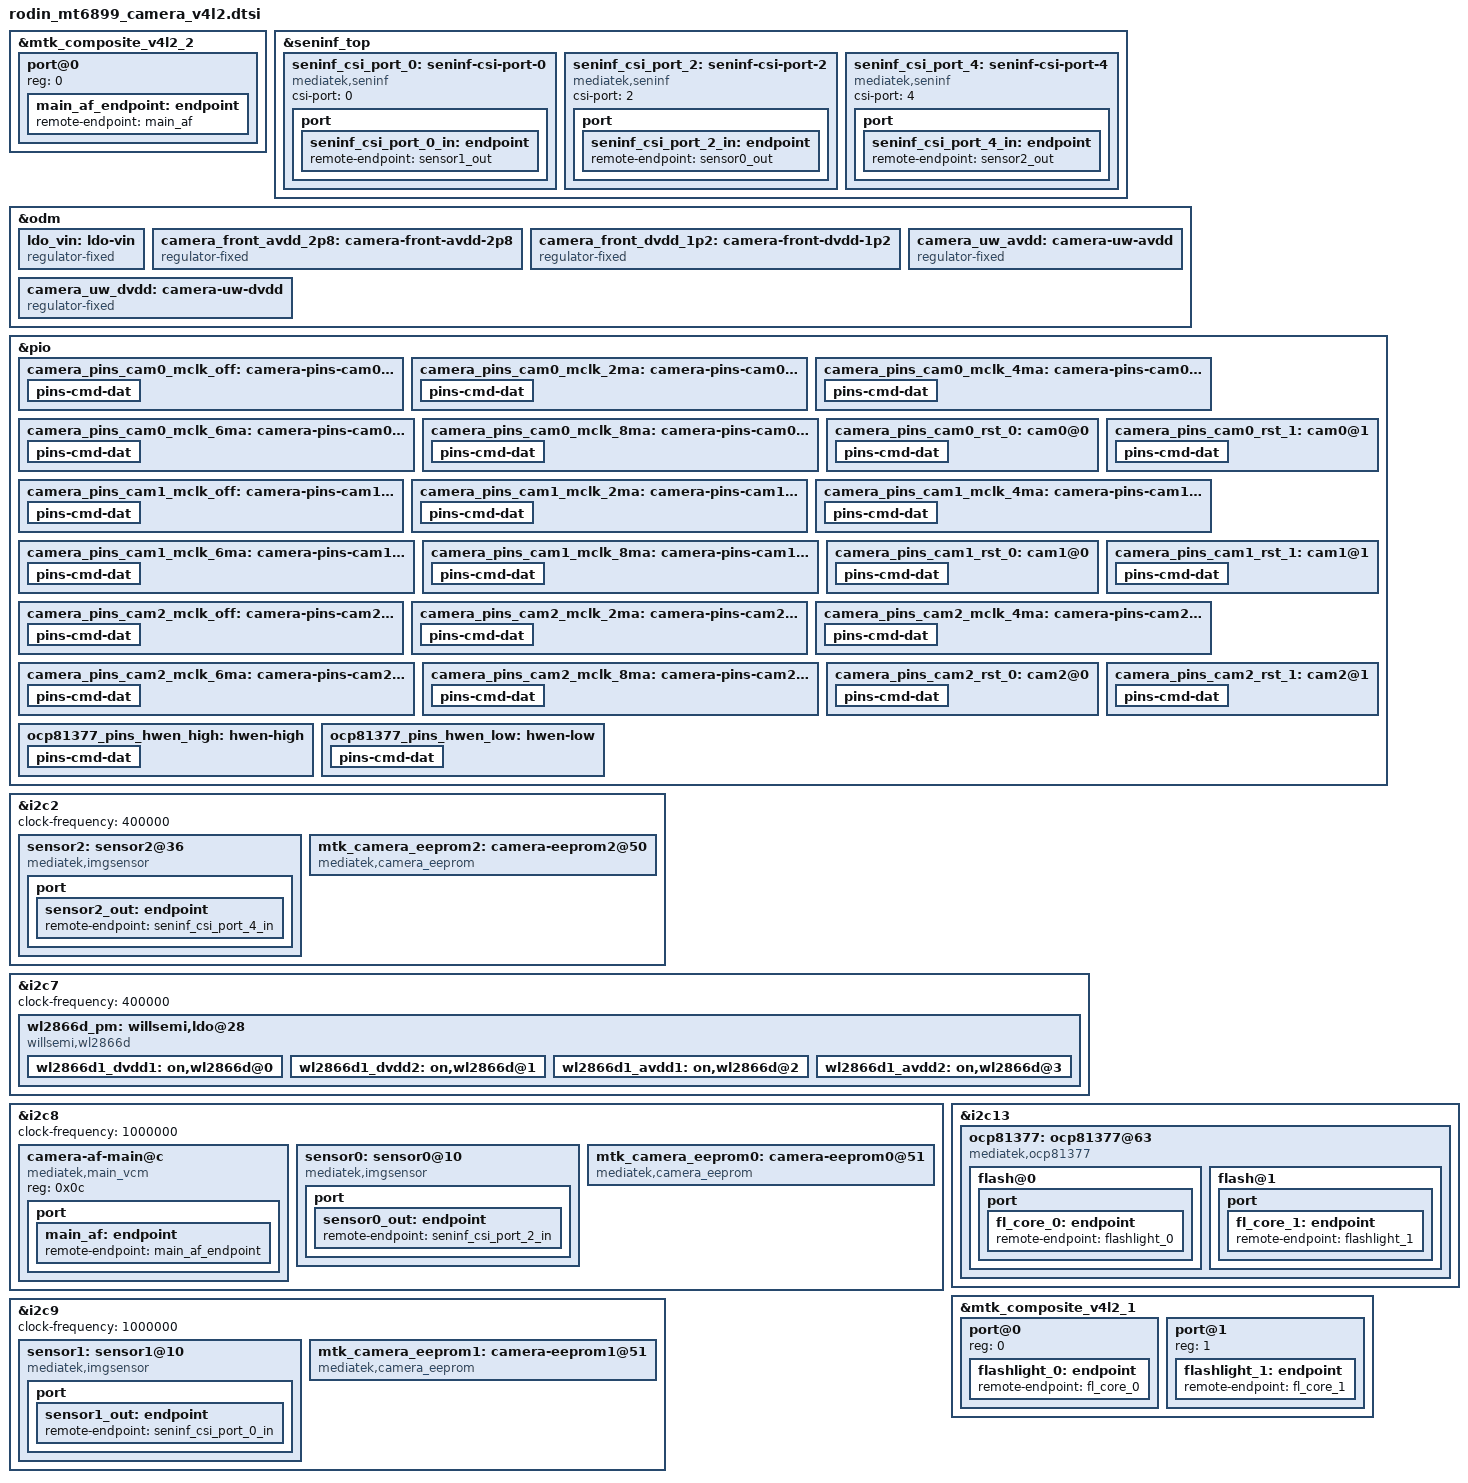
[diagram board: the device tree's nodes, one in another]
// SPDX-License-Identifier: GPL-2.0
/* Copyright (c) 2023 MediaTek Inc. */
#include <dt-bindings/clock/mt6899-clk.h>

&mtk_composite_v4l2_2 {
        #address-cells = <1>;
        #size-cells = <0>;
        port@0 {
                reg = <0>;
                main_af_endpoint: endpoint {
                        remote-endpoint = <&main_af>;
                };
        };
};


&seninf_top {
		seninf_csi_port_0: seninf-csi-port-0 {
			compatible = "mediatek,seninf";
			csi-port = "0";

			// nvmem-cells = <&csi_efuse0>;
			// nvmem-cell-names = "rg_csi";

			port {
				seninf_csi_port_0_in: endpoint {
					remote-endpoint = <&sensor1_out>;
				};
			};
		};

		seninf_csi_port_2: seninf-csi-port-2 {
			compatible = "mediatek,seninf";
			csi-port = "2";

			// nvmem-cells = <&csi_efuse2>;
			// nvmem-cell-names = "rg_csi";

			port {
				seninf_csi_port_2_in: endpoint {
					remote-endpoint = <&sensor0_out>;
				};
			};
		};

		seninf_csi_port_4: seninf-csi-port-4 {
			compatible = "mediatek,seninf";
			csi-port = "4";

			// nvmem-cells = <&csi_efuse4>;
			// nvmem-cell-names = "rg_csi";

			port {
				seninf_csi_port_4_in: endpoint {
					remote-endpoint = <&sensor2_out>;
				};
			};
		};
};

/* CAMERA GPIO fixed to regulator */
&odm {
	ldo_vin: ldo-vin {
		compatible = "regulator-fixed";
		regulator-name = "ldo-vin";
		regulator-min-microvolt = <1800000>;
		regulator-max-microvolt = <1800000>;
		enable-active-high;
		gpio = <&pio 121 0x0>;
	};
	camera_front_avdd_2p8: camera-front-avdd-2p8 {
		compatible = "regulator-fixed";
		regulator-name = "camera-front-avdd-2p8";
		regulator-min-microvolt = <2800000>;
		regulator-max-microvolt = <2800000>;
		enable-active-high;
		gpio = <&pio 120 0x0>;
	};
	camera_front_dvdd_1p2: camera-front-dvdd-1p2 {
		compatible = "regulator-fixed";
		regulator-name = "camera-front-dvdd-1p2";
		regulator-min-microvolt = <1200000>;
		regulator-max-microvolt = <1200000>;
		enable-active-high;
		gpio = <&pio 65 0x0>;
	};
	camera_uw_avdd: camera-uw-avdd {
		compatible = "regulator-fixed";
		regulator-name = "camera-uw-avdd";
		regulator-min-microvolt = <2800000>;
		regulator-max-microvolt = <2800000>;
		enable-active-high;
		gpio = <&pio 116 0x0>;
	};
	camera_uw_dvdd: camera-uw-dvdd {
		compatible = "regulator-fixed";
		regulator-name = "camera-uw-dvdd";
		regulator-min-microvolt = <1200000>;
		regulator-max-microvolt = <1200000>;
		enable-active-high;
		gpio = <&pio 124 0x0>;
	};
};

/* CAMERA GPIO standardization */
&pio {
	camera_pins_cam0_mclk_off: camera-pins-cam0-mclk-off {
		pins-cmd-dat {
			pinmux = <PINMUX_GPIO129__FUNC_GPIO129>;
			drive-strength = <1>;
		};
	};
	camera_pins_cam0_mclk_2ma: camera-pins-cam0-mclk-2ma {
		pins-cmd-dat {
			pinmux = <PINMUX_GPIO129__FUNC_CMMCLK6>;
			drive-strength = <0>;
		};
	};
	camera_pins_cam0_mclk_4ma: camera-pins-cam0-mclk-4ma {
		pins-cmd-dat {
			pinmux = <PINMUX_GPIO129__FUNC_CMMCLK6>;
			drive-strength = <1>;
		};
	};
	camera_pins_cam0_mclk_6ma: camera-pins-cam0-mclk-6ma {
		pins-cmd-dat {
			pinmux = <PINMUX_GPIO129__FUNC_CMMCLK6>;
			drive-strength = <2>;
		};
	};
	camera_pins_cam0_mclk_8ma: camera-pins-cam0-mclk-8ma {
		pins-cmd-dat {
			pinmux = <PINMUX_GPIO129__FUNC_CMMCLK6>;
			drive-strength = <3>;
		};
	};
	camera_pins_cam0_rst_0: cam0@0 {
		pins-cmd-dat {
			pinmux = <PINMUX_GPIO117__FUNC_GPIO117>;
			slew-rate = <1>;
			output-low;
		};
	};
	camera_pins_cam0_rst_1: cam0@1 {
		pins-cmd-dat {
			pinmux = <PINMUX_GPIO117__FUNC_GPIO117>;
			slew-rate = <1>;
			output-high;
		};
	};
	camera_pins_cam1_mclk_off: camera-pins-cam1-mclk-off {
		pins-cmd-dat {
			pinmux = <PINMUX_GPIO126__FUNC_GPIO126>;
			drive-strength = <1>;
		};
	};
	camera_pins_cam1_mclk_2ma: camera-pins-cam1-mclk-2ma {
		pins-cmd-dat {
			pinmux = <PINMUX_GPIO126__FUNC_CMMCLK3>;
			drive-strength = <0>;
		};
	};
	camera_pins_cam1_mclk_4ma: camera-pins-cam1-mclk-4ma {
		pins-cmd-dat {
			pinmux = <PINMUX_GPIO126__FUNC_CMMCLK3>;
			drive-strength = <1>;
		};
	};
	camera_pins_cam1_mclk_6ma: camera-pins-cam1-mclk-6ma {
		pins-cmd-dat {
			pinmux = <PINMUX_GPIO126__FUNC_CMMCLK3>;
			drive-strength = <2>;
		};
	};
	camera_pins_cam1_mclk_8ma: camera-pins-cam1-mclk-8ma {
		pins-cmd-dat {
			pinmux = <PINMUX_GPIO126__FUNC_CMMCLK3>;
			drive-strength = <3>;
		};
	};
	camera_pins_cam1_rst_0: cam1@0 {
		pins-cmd-dat {
			pinmux = <PINMUX_GPIO118__FUNC_GPIO118>;
			slew-rate = <1>;
			output-low;
		};
	};
	camera_pins_cam1_rst_1: cam1@1 {
		pins-cmd-dat {
			pinmux = <PINMUX_GPIO118__FUNC_GPIO118>;
			slew-rate = <1>;
			output-high;
		};
	};
	camera_pins_cam2_mclk_off: camera-pins-cam2-mclk-off {
		pins-cmd-dat {
			pinmux = <PINMUX_GPIO125__FUNC_GPIO125>;
			drive-strength = <1>;
		};
	};
	camera_pins_cam2_mclk_2ma: camera-pins-cam2-mclk-2ma {
		pins-cmd-dat {
			pinmux = <PINMUX_GPIO125__FUNC_CMMCLK2>;
			drive-strength = <0>;
		};
	};
	camera_pins_cam2_mclk_4ma: camera-pins-cam2-mclk-4ma {
		pins-cmd-dat {
			pinmux = <PINMUX_GPIO125__FUNC_CMMCLK2>;
			drive-strength = <1>;
		};
	};
	camera_pins_cam2_mclk_6ma: camera-pins-cam2-mclk-6ma {
		pins-cmd-dat {
			pinmux = <PINMUX_GPIO125__FUNC_CMMCLK2>;
			drive-strength = <2>;
		};
	};
	camera_pins_cam2_mclk_8ma: camera-pins-cam2-mclk-8ma {
		pins-cmd-dat {
			pinmux = <PINMUX_GPIO125__FUNC_CMMCLK2>;
			drive-strength = <3>;
		};
	};
	camera_pins_cam2_rst_0: cam2@0 {
		pins-cmd-dat {
			pinmux = <PINMUX_GPIO115__FUNC_GPIO115>;
			slew-rate = <1>;
			output-low;
		};
	};
	camera_pins_cam2_rst_1: cam2@1 {
		pins-cmd-dat {
			pinmux = <PINMUX_GPIO115__FUNC_GPIO115>;
			slew-rate = <1>;
			output-high;
		};
	};

};
/* CAMERA GPIO end */

&i2c2 {
	status = "okay";
	clock-frequency = <400000>;

	sensor2: sensor2@36 {
		compatible = "mediatek,imgsensor";
		sensor-names = "rodinsc820csultra_mipi_raw";
		reg = <0x36>;

		pinctrl-names = "mclk_off",
				"mclk_2mA",
				"mclk_4mA",
				"mclk_6mA",
				"mclk_8mA",
				"rst_low",
				"rst_high";
		pinctrl-0 = <&camera_pins_cam2_mclk_off>;
		pinctrl-1 = <&camera_pins_cam2_mclk_2ma>;
		pinctrl-2 = <&camera_pins_cam2_mclk_4ma>;
		pinctrl-3 = <&camera_pins_cam2_mclk_6ma>;
		pinctrl-4 = <&camera_pins_cam2_mclk_8ma>;
		pinctrl-5 = <&camera_pins_cam2_rst_0>;
		pinctrl-6 = <&camera_pins_cam2_rst_1>;

		avdd1-supply = <&ldo_vin>;
		avdd-supply = <&camera_uw_avdd>;
		dvdd-supply = <&camera_uw_dvdd>;
		dovdd-supply = <&mt6363_vufs18>;

		clocks = <&topckgen_clk CLK_TOP_UNIVPLL_192M_D32>,
			<&topckgen_clk CLK_TOP_UNIVPLL_192M_D16>,
			<&topckgen_clk CLK_TOP_F26M_CK_D2>,
			<&topckgen_clk CLK_TOP_UNIVPLL_192M_D10>,
			<&topckgen_clk CLK_TOP_UNIVPLL_192M_D8>,
			<&topckgen_clk CLK_TOP_UNIVPLL_D6_D16>,
			<&topckgen_clk CLK_TOP_UNIVPLL_D6_D8>,
			<&vlp_cksys_clk CLK_VLP_CK_CAMTG2_SEL>;
		clock-names = "6", "12", "13", "19.2", "24", "26", "52", "mclk";

		status = "okay";
		port {
			sensor2_out: endpoint {
				remote-endpoint = <&seninf_csi_port_4_in>;
			};
		};
	};

	mtk_camera_eeprom2:camera-eeprom2@50 {
		compatible = "mediatek,camera_eeprom";
		reg = <0x50 0 0>;
		names = "rodinsc820csultra_mtk_eeprom_aac",
			"rodinsc820csultra_mtk_eeprom_sunny";
		status = "okay";
	};
};

&i2c7 {
	status = "okay";
	clock-frequency = <400000>;

	wl2866d_pm:willsemi,ldo@28 {
		compatible = "willsemi,wl2866d";
		reg = <0x28>;/*slave address*/
        index = <0>;

		wl2866d1_dvdd1:on,wl2866d@0{
			offset = /bits/ 16 <0x0000>;
			regulator-name ="dvdd1";
			regulator-min-microvolt = <600000>;
			regulator-max-microvolt = <1800000>;
			min-dropout-voltage = <80000>;
			iout_ua = <500000>;
			init-voltage = <1100000>;
		};

		wl2866d1_dvdd2:on,wl2866d@1{
			offset = /bits/ 16 <0x0001>;
			regulator-name ="dvdd2";
			regulator-min-microvolt = <600000>;
			regulator-max-microvolt = <1800000>;
			min-dropout-voltage = <80000>;
			iout_ua = <500000>;
			init-voltage = <1200000>;
		};

		wl2866d1_avdd1:on,wl2866d@2{
			offset = /bits/ 16 <0x0002>;
			regulator-name ="avdd1";
			regulator-min-microvolt = <1200000>;
			regulator-max-microvolt = <4300000>;
			min-dropout-voltage = <90000>;
			iout_ua = <300000>;
			init-voltage = <3100000>;
		};

		wl2866d1_avdd2:on,wl2866d@3{
			offset = /bits/ 16 <0x0003>;
			regulator-name ="avdd2";
			regulator-min-microvolt = <1200000>;
			regulator-max-microvolt = <4300000>;
			min-dropout-voltage = <90000>;
			iout_ua = <300000>;
			init-voltage = <2800000>;
		};
	};
};

&i2c8 {
	status = "okay";
	clock-frequency = <1000000>;

        camera-af-main@c {
                compatible = "mediatek,main_vcm";
                reg = <0x0c>;
                /*vin-supply = <&fan53870_l3>;*/
                port {
                        main_af: endpoint {
                                remote-endpoint = <&main_af_endpoint>;
                        };
                };
        };

	sensor0: sensor0@10 {
		compatible = "mediatek,imgsensor";
		sensor-names = "rodinimx882wide_mipi_raw";
		reg = <0x10>;

		#thermal-sensor-cells = <0>;

		pinctrl-names = "mclk_off",
				"mclk_2mA",
				"mclk_4mA",
				"mclk_6mA",
				"mclk_8mA",
				"rst_low",
				"rst_high";
		pinctrl-0 = <&camera_pins_cam0_mclk_off>;
		pinctrl-1 = <&camera_pins_cam0_mclk_2ma>;
		pinctrl-2 = <&camera_pins_cam0_mclk_4ma>;
		pinctrl-3 = <&camera_pins_cam0_mclk_6ma>;
		pinctrl-4 = <&camera_pins_cam0_mclk_8ma>;
		pinctrl-5 = <&camera_pins_cam0_rst_0>;
		pinctrl-6 = <&camera_pins_cam0_rst_1>;

		avdd1-supply = <&ldo_vin>;
		avdd-supply = <&wl2866d1_avdd2>;
		dvdd-supply = <&wl2866d1_dvdd1>;
		afvdd-supply = <&wl2866d1_avdd1>;
		dovdd-supply = <&mt6363_vufs18>;


		clocks = <&topckgen_clk CLK_TOP_UNIVPLL_192M_D32>,
			<&topckgen_clk CLK_TOP_UNIVPLL_192M_D16>,
			<&topckgen_clk CLK_TOP_F26M_CK_D2>,
			<&topckgen_clk CLK_TOP_UNIVPLL_192M_D10>,
			<&topckgen_clk CLK_TOP_UNIVPLL_192M_D8>,
			<&topckgen_clk CLK_TOP_UNIVPLL_D6_D16>,
			<&topckgen_clk CLK_TOP_UNIVPLL_D6_D8>,
			<&vlp_cksys_clk CLK_VLP_CK_CAMTG6_SEL>;
		clock-names = "6", "12", "13", "19.2", "24", "26", "52", "mclk";


		status = "okay";
		port {
			sensor0_out: endpoint {
				remote-endpoint = <&seninf_csi_port_2_in>;
			};
		};
	};

	mtk_camera_eeprom0:camera-eeprom0@51 {
		compatible = "mediatek,camera_eeprom";
		reg = <0x51>;
		names = "rodinimx882wide_mtk_eeprom_aac",
			"rodinimx882wide_mtk_eeprom_ofilm";
		status = "okay";
	};
};

&i2c9 {
	status = "okay";
	clock-frequency = <1000000>;

	sensor1: sensor1@10 {
		compatible = "mediatek,imgsensor";
		sensor-names = "rodinov20bfront_mipi_raw";
		reg = <0x10>;

		#thermal-sensor-cells = <0>;

		pinctrl-names = "mclk_off",
				"mclk_2mA",
				"mclk_4mA",
				"mclk_6mA",
				"mclk_8mA",
				"rst_low",
				"rst_high";
		pinctrl-0 = <&camera_pins_cam1_mclk_off>;
		pinctrl-1 = <&camera_pins_cam1_mclk_2ma>;
		pinctrl-2 = <&camera_pins_cam1_mclk_4ma>;
		pinctrl-3 = <&camera_pins_cam1_mclk_6ma>;
		pinctrl-4 = <&camera_pins_cam1_mclk_8ma>;
		pinctrl-5 = <&camera_pins_cam1_rst_0>;
		pinctrl-6 = <&camera_pins_cam1_rst_1>;

		avdd1-supply = <&ldo_vin>;
		avdd-supply = <&camera_front_avdd_2p8>;
		dvdd-supply = <&wl2866d1_dvdd2>;
		dovdd-supply = <&mt6363_vufs18>;

		clocks = <&topckgen_clk CLK_TOP_UNIVPLL_192M_D32>,
			<&topckgen_clk CLK_TOP_UNIVPLL_192M_D16>,
			<&topckgen_clk CLK_TOP_F26M_CK_D2>,
			<&topckgen_clk CLK_TOP_UNIVPLL_192M_D10>,
			<&topckgen_clk CLK_TOP_UNIVPLL_192M_D8>,
			<&topckgen_clk CLK_TOP_UNIVPLL_D6_D16>,
			<&topckgen_clk CLK_TOP_UNIVPLL_D6_D8>,
			<&vlp_cksys_clk CLK_VLP_CK_CAMTG3_SEL>;
		clock-names = "6", "12", "13", "19.2", "24", "26", "52", "mclk";

		status = "okay";
		port {
			sensor1_out: endpoint {
				remote-endpoint = <&seninf_csi_port_0_in>;
			};
		};
	};

	mtk_camera_eeprom1:camera-eeprom1@51 {
		compatible = "mediatek,camera_eeprom";
		reg = <0x51>;
		names = "rodinov20bfront_mtk_eeprom_aac",
			"rodinov20bfront_mtk_eeprom_sunny";
		status = "okay";
	};
};

&i2c13 {
	#address-cells = <1>;
	#size-cells = <0>;
	ocp81377:ocp81377@63 {
		compatible = "mediatek,ocp81377";
		#address-cells = <1>;
		#size-cells = <0>;
		reg = <0x63>;
		#cooling-cells = <2>;
		pinctrl-names = "hwen-high", "hwen-low";
		pinctrl-0 = <&ocp81377_pins_hwen_high>;
		pinctrl-1 = <&ocp81377_pins_hwen_low>;
		status = "okay";
		flash@0{
			reg = <0>;
			type = <0>;
			ct = <0>;
			part = <0>;
			port {
				fl_core_0: endpoint {
					remote-endpoint = <&flashlight_0>;
				};
			};
		};
		flash@1{
			reg = <1>;
			type = <0>;
			ct = <1>;
			part = <0>;
			port {
				fl_core_1: endpoint {
					remote-endpoint = <&flashlight_1>;
				};
			};
		};
	};
};

&pio {
	ocp81377_pins_hwen_high: hwen-high {
		pins-cmd-dat {
			pinmux = <PINMUX_GPIO62__FUNC_GPIO62>;
			slew-rate = <1>;
			output-high;
		};
	};

	ocp81377_pins_hwen_low: hwen-low {
		pins-cmd-dat {
			pinmux = <PINMUX_GPIO62__FUNC_GPIO62>;
			slew-rate = <1>;
			output-low;
		};
	};
};

&mtk_composite_v4l2_1 {
	#address-cells = <1>;
	#size-cells = <0>;
	port@0 {
		reg = <0>;
		flashlight_0: endpoint {
			remote-endpoint = <&fl_core_0>;
		};
	};
	port@1 {
		reg = <1>;
		flashlight_1: endpoint {
			remote-endpoint = <&fl_core_1>;
		};
	};
};
